# XHSC_HC32L12X register map
Vendor: XHSC Co.Ltd; Series: ARMCM0P; File version: 1.0
CPU: CM0P r0p0, little endian, no MPU, no FPU, 3 interrupt priority bits
Registers are 32-bit, read-write, reset 0x0 unless marked. A register's access mark holds for its fields unless they carry their own. Offsets are from the block's base; [hi:lo] are bit positions; {n}, {i} and the like mark numbered series; 'fields as' and 'values as' point back to an identical list.

## TIM3_MODE23
Base 0x40009800; alternate view of TIM3_MODE0
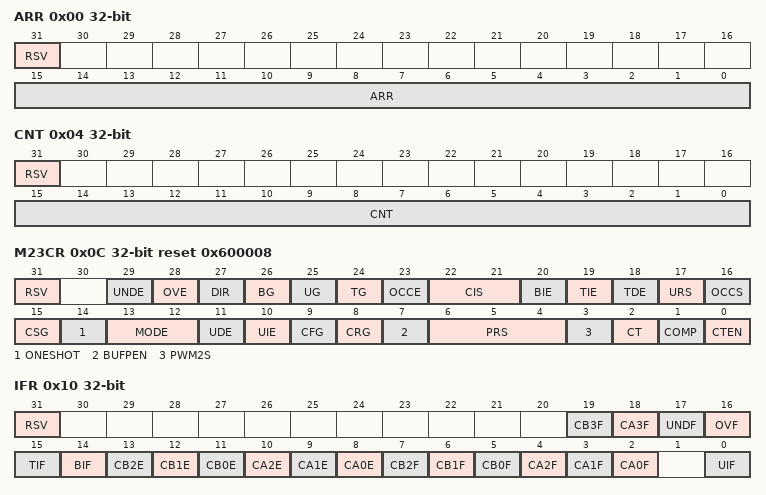
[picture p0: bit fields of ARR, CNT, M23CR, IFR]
0x00 ARR (reset mask 0xFFFF)
  [31] RSV, [15:0] ARR
0x04 CNT (reset mask 0xFFFF)
  [31] RSV, [15:0] CNT
0x0C M23CR reset 0x600008 (reset mask 0x3FFFFFFF)
  [31] RSV, [29] UNDE, [28] OVE, [27] DIR, [26] BG wo, [25] UG wo, [24] TG wo, [23] OCCE, [22:21] CIS, [20] BIE, [19] TIE, [18] TDE, [17] URS, [16] OCCS, [15] CSG, [14] ONESHOT, [13:12] MODE, [11] UDE, [10] UIE, [9] CFG, [8] CRG, [7] BUFPEN, [6:4] PRS, [3] PWM2S, [2] CT, [1] COMP, [0] CTEN
0x10 IFR ro (reset mask 0xFFFFD)
  [31] RSV, [19] CB3F, [18] CA3F, [17] UNDF, [16] OVF, [15] TIF, [14] BIF, [13] CB2E, [12] CB1E, [11] CB0E, [10] CA2E, [9] CA1E, [8] CA0E, [7] CB2F, [6] CB1F, [5] CB0F, [4] CA2F, [3] CA1F, [2] CA0F, [0] UIF
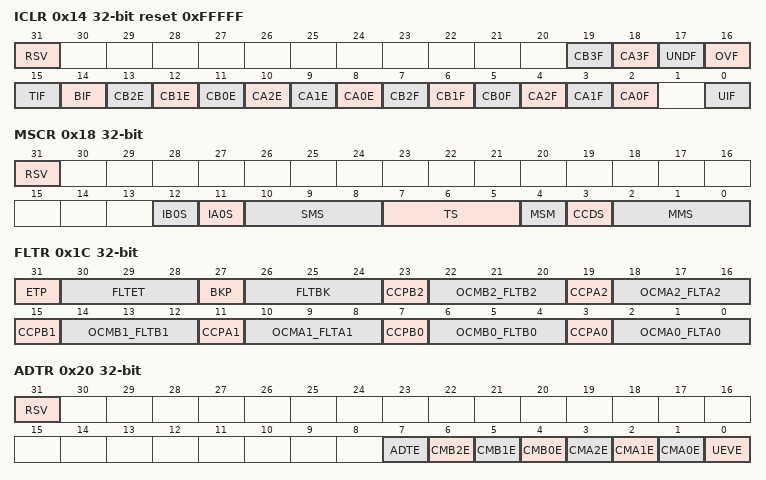
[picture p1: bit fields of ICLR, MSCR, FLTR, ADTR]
0x14 ICLR wo reset 0xFFFFF (reset mask 0xFFFFD)
  fields as IFR
0x18 MSCR (reset mask 0x1FFF)
  [31] RSV, [12] IB0S, [11] IA0S, [10:8] SMS, [7:5] TS, [4] MSM, [3] CCDS, [2:0] MMS
0x1C FLTR
  [31] ETP, [30:28] FLTET, [27] BKP, [26:24] FLTBK, [23] CCPB2, [22:20] OCMB2_FLTB2, [19] CCPA2, [18:16] OCMA2_FLTA2, [15] CCPB1, [14:12] OCMB1_FLTB1, [11] CCPA1, [10:8] OCMA1_FLTA1, [7] CCPB0, [6:4] OCMB0_FLTB0, [3] CCPA0, [2:0] OCMA0_FLTA0
0x20 ADTR (reset mask 0xFF)
  [31] RSV, [7] ADTE, [6] CMB2E, [5] CMB1E, [4] CMB0E, [3] CMA2E, [2] CMA1E, [1] CMA0E, [0] UEVE
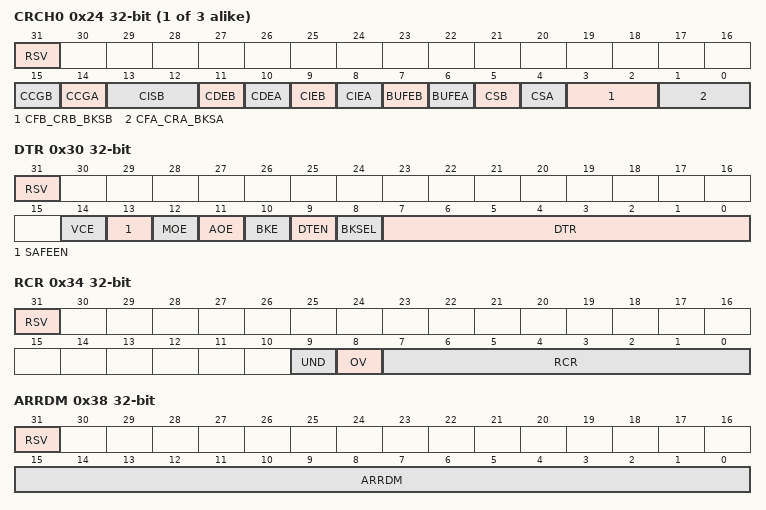
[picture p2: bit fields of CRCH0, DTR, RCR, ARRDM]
{0x24+4i} CRCH{i} (reset mask 0xFFFF) (i=0..2)
  [31] RSV, [15] CCGB, [14] CCGA, [13:12] CISB, [11] CDEB, [10] CDEA, [9] CIEB, [8] CIEA, [7] BUFEB, [6] BUFEA, [5] CSB, [4] CSA, [3:2] CFB_CRB_BKSB, [1:0] CFA_CRA_BKSA
0x30 DTR (reset mask 0x7FFF)
  [31] RSV, [14] VCE, [13] SAFEEN, [12] MOE, [11] AOE, [10] BKE, [9] DTEN, [8] BKSEL, [7:0] DTR
0x34 RCR (reset mask 0x3FF)
  [31] RSV, [9] UND, [8] OV, [7:0] RCR
0x38 ARRDM (reset mask 0xFFFF)
  [31] RSV, [15:0] ARRDM
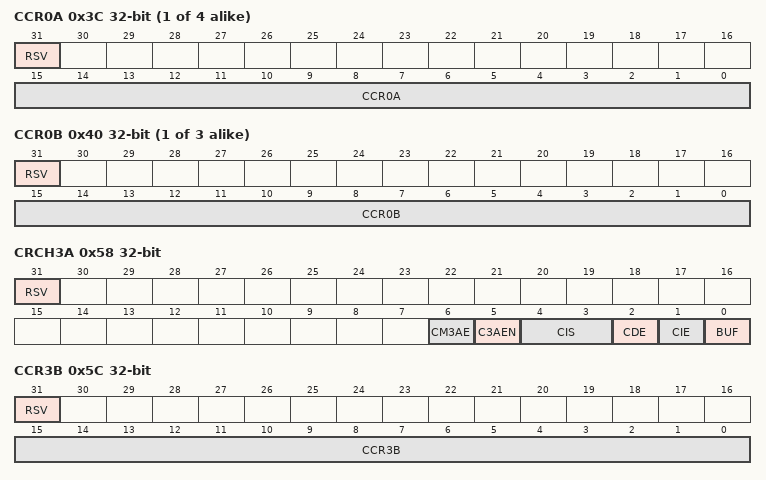
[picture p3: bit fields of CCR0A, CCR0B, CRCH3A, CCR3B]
{0x3C+8i} CCR{i}A (reset mask 0xFFFF) (i=0..3)
  [31] RSV, [15:0] CCR{i}A
{0x40+8i} CCR{i}B (reset mask 0xFFFF) (i=0..2)
  [31] RSV, [15:0] CCR{i}B
0x58 CRCH3A (reset mask 0x7F)
  [31] RSV, [6] CM3AE, [5] C3AEN, [4:3] CIS, [2] CDE, [1] CIE, [0] BUF
0x5C CCR3B (reset mask 0xFFFF)
  [31] RSV, [15:0] CCR3B
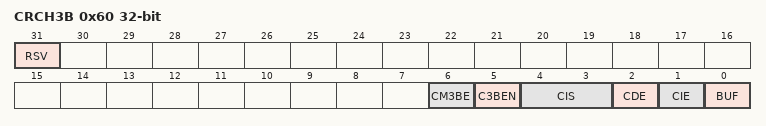
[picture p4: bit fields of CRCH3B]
0x60 CRCH3B (reset mask 0x7F)
  [31] RSV, [6] CM3BE, [5] C3BEN, [4:3] CIS, [2] CDE, [1] CIE, [0] BUF

## TRNG
Base 0x40008C00
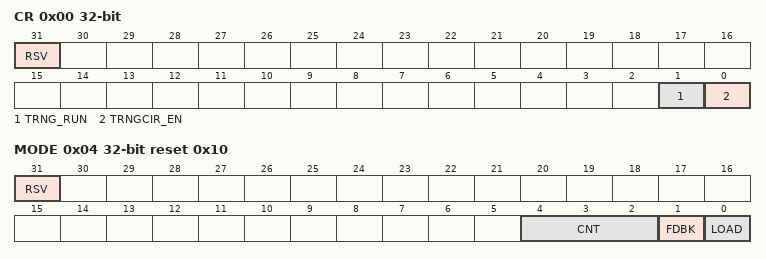
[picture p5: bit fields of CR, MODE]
0x00 CR (reset mask 0x3)
  [31] RSV, [1] TRNG_RUN, [0] TRNGCIR_EN
0x04 MODE reset 0x10 (reset mask 0x1F)
  [31] RSV, [4:2] CNT, [1] FDBK, [0] LOAD
0x0C DATA0 ro
0x10 DATA1 ro

## USART0 — desc USART
Base 0x4000A000
Same registers: USART1 0x4000A400
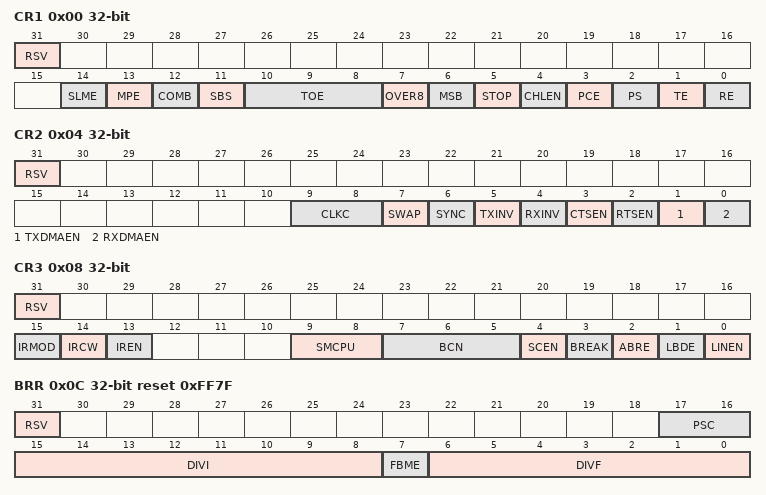
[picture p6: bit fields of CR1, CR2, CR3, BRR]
0x00 CR1 (reset mask 0x7FFF)
  [31] RSV, [14] SLME, [13] MPE, [12] COMB, [11] SBS, [10:8] TOE, [7] OVER8, [6] MSB, [5] STOP, [4] CHLEN, [3] PCE, [2] PS, [1] TE, [0] RE
0x04 CR2 (reset mask 0x3FF)
  [31] RSV, [9:8] CLKC, [7] SWAP, [6] SYNC, [5] TXINV, [4] RXINV, [3] CTSEN, [2] RTSEN, [1] TXDMAEN, [0] RXDMAEN
0x08 CR3 (reset mask 0xE3FF)
  [31] RSV, [15] IRMOD, [14] IRCW, [13] IREN, [9:8] SMCPU, [7:5] BCN, [4] SCEN, [3] BREAK, [2] ABRE, [1] LBDE, [0] LINEN
0x0C BRR reset 0xFF7F (reset mask 0x3FFFF)
  [31] RSV, [17:16] PSC, [15:8] DIVI, [7] FBME, [6:0] DIVF
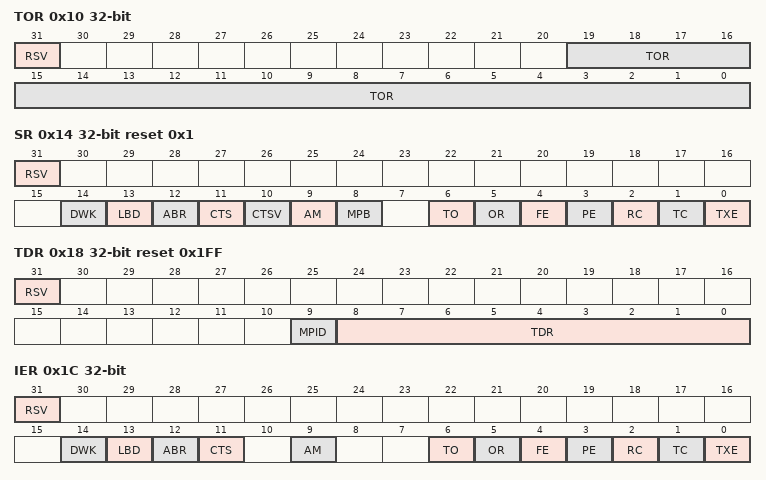
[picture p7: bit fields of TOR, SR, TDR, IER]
0x10 TOR (reset mask 0xFFFFF)
  [31] RSV, [19:0] TOR
0x14 SR ro reset 0x1 (reset mask 0x7F7F)
  [31] RSV, [14] DWK, [13] LBD, [12] ABR, [11] CTS, [10] CTSV, [9] AM, [8] MPB, [6] TO, [5] OR, [4] FE, [3] PE, [2] RC, [1] TC, [0] TXE
0x18 TDR reset 0x1FF (reset mask 0x3FF)
  [31] RSV, [9] MPID, [8:0] TDR
0x1C IER (reset mask 0x7A7F)
  [31] RSV, [14] DWK, [13] LBD, [12] ABR, [11] CTS, [9] AM, [6] TO, [5] OR, [4] FE, [3] PE, [2] RC, [1] TC, [0] TXE
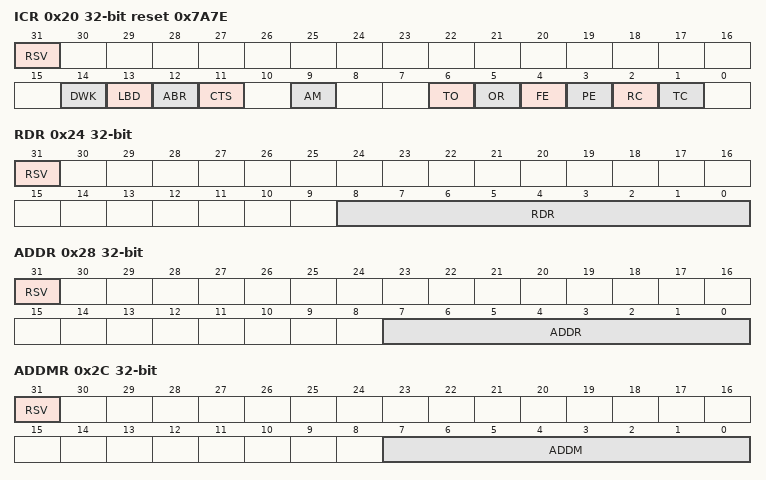
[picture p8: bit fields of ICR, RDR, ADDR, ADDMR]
0x20 ICR wo reset 0x7A7E (reset mask 0x7A7E)
  [31] RSV, [14] DWK, [13] LBD, [12] ABR, [11] CTS, [9] AM, [6] TO, [5] OR, [4] FE, [3] PE, [2] RC, [1] TC
0x24 RDR ro (reset mask 0x1FF)
  [31] RSV, [8:0] RDR
0x28 ADDR (reset mask 0xFF)
  [31] RSV, [7:0] ADDR
0x2C ADDMR (reset mask 0xFF)
  [31] RSV, [7:0] ADDM
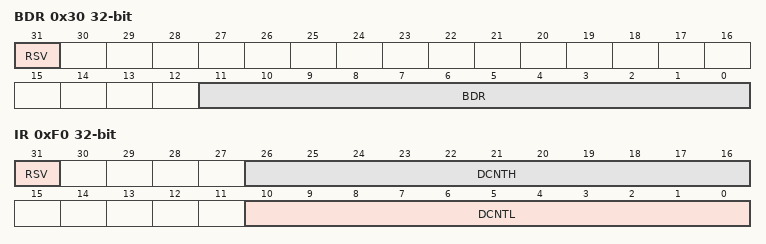
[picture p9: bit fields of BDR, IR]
0x30 BDR ro (reset mask 0xFFF)
  [31] RSV, [11:0] BDR
0xF0 IR (reset mask 0x7FF07FF)
  [31] RSV, [26:16] DCNTH, [10:0] DCNTL

## VC0 — desc VC
Base 0x40002800
Same registers: VC1 0x40002810
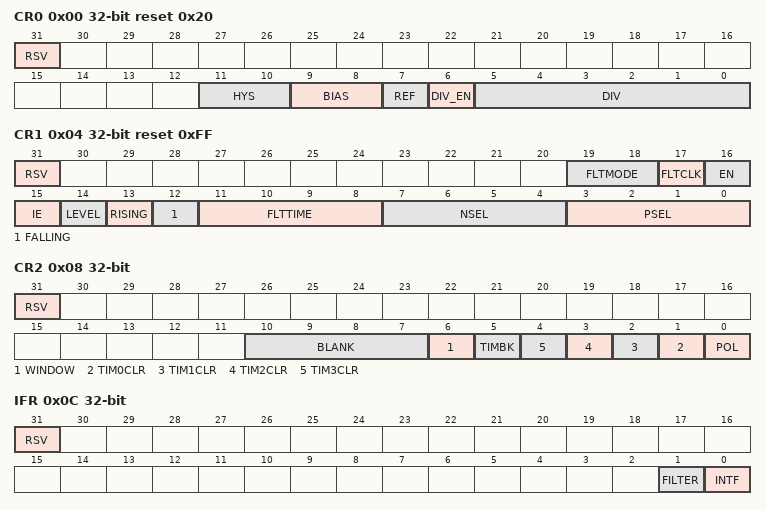
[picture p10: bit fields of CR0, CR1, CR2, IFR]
0x00 CR0 reset 0x20 (reset mask 0xF7F)
  [31] RSV, [11:10] HYS, [9:8] BIAS, [7] REF, [6] DIV_EN, [5:0] DIV
0x04 CR1 reset 0xFF (reset mask 0xFFFFF)
  [31] RSV, [19:18] FLTMODE, [17] FLTCLK, [16] EN, [15] IE, [14] LEVEL, [13] RISING, [12] FALLING, [11:8] FLTTIME, [7:4] NSEL, [3:0] PSEL
0x08 CR2 (reset mask 0x771)
  [31] RSV, [10:7] BLANK, [6] WINDOW, [5] TIMBK, [n+1] TIM{n}CLR (n=0..3), [0] POL
0x0C IFR (reset mask 0x3)
  [31] RSV, [1] FILTER ro, [0] INTF

## VCTRIM
Base 0x40002820
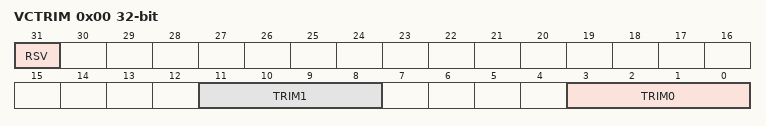
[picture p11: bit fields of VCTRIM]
0x00 VCTRIM (reset mask 0xF0F)
  [31] RSV, [11:8] TRIM1, [3:0] TRIM0

## WWDT
Base 0x4000B800
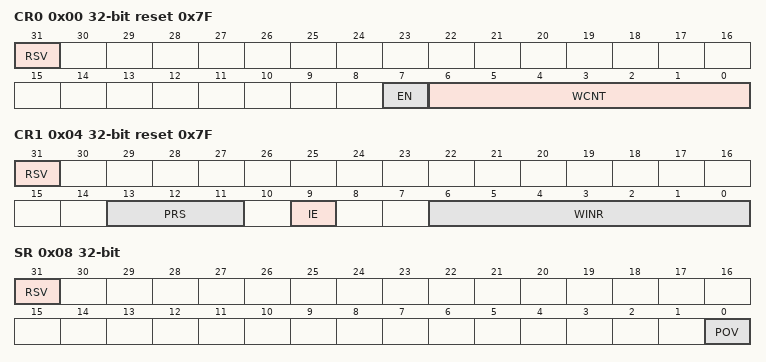
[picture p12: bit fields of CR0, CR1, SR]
0x00 CR0 reset 0x7F (reset mask 0xFF)
  [31] RSV, [7] EN, [6:0] WCNT
0x04 CR1 reset 0x7F (reset mask 0x3A7F)
  [31] RSV, [13:11] PRS, [9] IE, [6:0] WINR
0x08 SR (reset mask 0x1)
  [31] RSV, [0] POV
